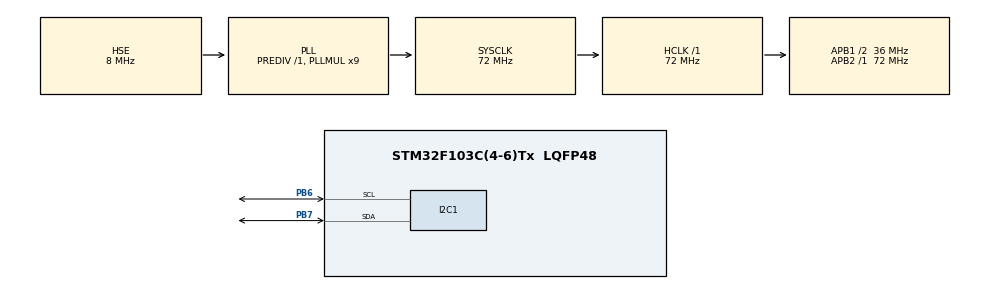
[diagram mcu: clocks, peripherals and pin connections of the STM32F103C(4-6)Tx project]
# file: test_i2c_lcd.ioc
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Mcu.Family=STM32F1
Mcu.Name=STM32F103C(4-6)Tx
Mcu.Package=LQFP48
NVIC.PriorityGroup=NVIC_PRIORITYGROUP_4
PA13.Mode=Serial_Wire
PA13.Signal=SYS_JTMS-SWDIO
PA14.Mode=Serial_Wire
PA14.Signal=SYS_JTCK-SWCLK
PB6.Mode=I2C
PB6.Signal=I2C1_SCL
PB7.Mode=I2C
PB7.Signal=I2C1_SDA
PD0-OSC_IN.Mode=HSE-External-Oscillator
PD0-OSC_IN.Signal=RCC_OSC_IN
PD1-OSC_OUT.Mode=HSE-External-Oscillator
PD1-OSC_OUT.Signal=RCC_OSC_OUT
ProjectManager.HeapSize=0x200
ProjectManager.StackSize=0x400
ProjectManager.TargetToolchain=MDK-ARM V5
RCC.AHBFreq_Value=72000000
RCC.APB1CLKDivider=RCC_HCLK_DIV2
RCC.APB1Freq_Value=36000000
RCC.APB1TimFreq_Value=72000000
RCC.APB2Freq_Value=72000000
RCC.APB2TimFreq_Value=72000000
RCC.HCLKFreq_Value=72000000
RCC.PLLMUL=RCC_PLL_MUL9
RCC.PLLSourceVirtual=RCC_PLLSOURCE_HSE
RCC.SYSCLKFreq_VALUE=72000000
RCC.SYSCLKSource=RCC_SYSCLKSOURCE_PLLCLK
RCC.USBFreq_Value=72000000
VP_TIM2_VS_ClockSourceINT.Mode=Internal
board=custom

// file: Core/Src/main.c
/* USER CODE BEGIN Header */
/**
  ******************************************************************************
  * @file           : main.c
  * @brief          : Main program body
  ******************************************************************************
  * @attention
  *
  * Copyright (c) 2024 STMicroelectronics.
  * All rights reserved.
  *
  * This software is licensed under terms that can be found in the LICENSE file
  * in the root directory of this software component.
  * If no LICENSE file comes with this software, it is provided AS-IS.
  *
  ******************************************************************************
  */
/* USER CODE END Header */
#include "main.h"
#include "i2c-lcd.h"
#include "string.h"

I2C_HandleTypeDef hi2c1;

TIM_HandleTypeDef htim2;

void SystemClock_Config(void);
static void MX_GPIO_Init(void);
static void MX_I2C1_Init(void);
static void MX_TIM2_Init(void);
/* USER CODE BEGIN PFP */
//#define LCD_Address 0x4E

//char dataLCD[100];

//void Lcd_write_command(char command){
//	char data_u, data_l;
//	uint8_t data_t[4];
//	data_u = (command & 0xf0);
//	data_l = ((command<<4) & 0xf0);
//	data_t[0] = data_u | 0x0C; //en=1, rs=0
//	data_t[1] = data_u | 0x08; //en=0, rs=0
//	data_t[2] = data_l | 0x0C; //en=1, rs=0
//	data_t[3] = data_l | 0x08; //en=0, rs=0
//	HAL_I2C_Master_Transmit(&hi2c1, LCD_Address,
//										(uint8_t *) data_t, 4, 100);
//}
//void Lcd_write_data(char data){
//	char data_u, data_l;
//	uint8_t data_t[4];
//	data_u = (data & 0xf0);
//	data_l = ((data<<4) & 0xf0);
//	data_t[0] = data_u | 0x0D; //en=1, rs=1
//	data_t[1] = data_u | 0x09; //en=0, rs=1
//	data_t[2] = data_l | 0x0D; //en=1, rs=1
//	data_t[3] = data_l | 0x09; //en=0, rs=1
//	HAL_I2C_Master_Transmit(&hi2c1, LCD_Address,
//										(uint8_t *) data_t, 4, 100);
//}
//void Lcd_init(void){
//	Lcd_write_command(0x03);
//	HAL_Delay(50);
//	Lcd_write_command(0x02);
//	HAL_Delay(50);
//	Lcd_write_command(0x06);
//	HAL_Delay(50);
//	Lcd_write_command(0x0c);
//	HAL_Delay(50);
//	Lcd_write_command(0x28);
//	HAL_Delay(50);
//	Lcd_write_command(0x80);
//}
//void Lcd_write_string (char *str){
//	while (*str) Lcd_write_data (*str++);
//}

//void Lcd_delete(void){
//	Lcd_write_command(0x01);//delete display
//}
/* USER CODE END PFP */

int main(void)
{

  /* MCU Configuration--------------------------------------------------------*/

  /* Reset of all peripherals, Initializes the Flash interface and the Systick. */
  HAL_Init();
  SystemClock_Config();
  MX_GPIO_Init();
  MX_I2C1_Init();
  MX_TIM2_Init();
	lcd_init();

//	Lcd_init();
//	Lcd_delete();
//	HAL_Delay(50);
//
//	Lcd_write_command(0x80);
//	Lcd_write_string("Hieu");
//	Lcd_write_command(0xC0);//row2
//	Lcd_write_string("Beo");
//	HAL_Delay(2000);
//	Lcd_delete();
//	HAL_Delay(50);

  /* Infinite loop */
  while (1)
  {
		lcd_put_cur(0,0);
		lcd_send_string("Hello Hieu");
		lcd_put_cur(1,1);
		lcd_send_string("OKE");
		HAL_Delay(1000);
		lcd_clear();
  }
}

void SystemClock_Config(void)
{
  RCC_OscInitTypeDef RCC_OscInitStruct = {0};
  RCC_ClkInitTypeDef RCC_ClkInitStruct = {0};

  /** Initializes the RCC Oscillators according to the specified parameters
  * in the RCC_OscInitTypeDef structure.
  */
  RCC_OscInitStruct.OscillatorType = RCC_OSCILLATORTYPE_HSE;
  RCC_OscInitStruct.HSEState = RCC_HSE_ON;
  RCC_OscInitStruct.HSEPredivValue = RCC_HSE_PREDIV_DIV1;
  RCC_OscInitStruct.HSIState = RCC_HSI_ON;
  RCC_OscInitStruct.PLL.PLLState = RCC_PLL_ON;
  RCC_OscInitStruct.PLL.PLLSource = RCC_PLLSOURCE_HSE;
  RCC_OscInitStruct.PLL.PLLMUL = RCC_PLL_MUL9;
  if (HAL_RCC_OscConfig(&RCC_OscInitStruct) != HAL_OK)
  {
    Error_Handler();
  }

  /** Initializes the CPU, AHB and APB buses clocks
  */
  RCC_ClkInitStruct.ClockType = RCC_CLOCKTYPE_HCLK|RCC_CLOCKTYPE_SYSCLK
                              |RCC_CLOCKTYPE_PCLK1|RCC_CLOCKTYPE_PCLK2;
  RCC_ClkInitStruct.SYSCLKSource = RCC_SYSCLKSOURCE_PLLCLK;
  RCC_ClkInitStruct.AHBCLKDivider = RCC_SYSCLK_DIV1;
  RCC_ClkInitStruct.APB1CLKDivider = RCC_HCLK_DIV2;
  RCC_ClkInitStruct.APB2CLKDivider = RCC_HCLK_DIV1;

  if (HAL_RCC_ClockConfig(&RCC_ClkInitStruct, FLASH_LATENCY_2) != HAL_OK)
  {
    Error_Handler();
  }
}

static void MX_I2C1_Init(void)
{

  hi2c1.Instance = I2C1;
  hi2c1.Init.ClockSpeed = 100000;
  hi2c1.Init.DutyCycle = I2C_DUTYCYCLE_2;
  hi2c1.Init.OwnAddress1 = 0;
  hi2c1.Init.AddressingMode = I2C_ADDRESSINGMODE_7BIT;
  hi2c1.Init.DualAddressMode = I2C_DUALADDRESS_DISABLE;
  hi2c1.Init.OwnAddress2 = 0;
  hi2c1.Init.GeneralCallMode = I2C_GENERALCALL_DISABLE;
  hi2c1.Init.NoStretchMode = I2C_NOSTRETCH_DISABLE;
  if (HAL_I2C_Init(&hi2c1) != HAL_OK)
  {
    Error_Handler();
  }

}

static void MX_TIM2_Init(void)
{

  TIM_ClockConfigTypeDef sClockSourceConfig = {0};
  TIM_MasterConfigTypeDef sMasterConfig = {0};

  htim2.Instance = TIM2;
  htim2.Init.Prescaler = 0;
  htim2.Init.CounterMode = TIM_COUNTERMODE_UP;
  htim2.Init.Period = 65535;
  htim2.Init.ClockDivision = TIM_CLOCKDIVISION_DIV1;
  htim2.Init.AutoReloadPreload = TIM_AUTORELOAD_PRELOAD_DISABLE;
  if (HAL_TIM_Base_Init(&htim2) != HAL_OK)
  {
    Error_Handler();
  }
  sClockSourceConfig.ClockSource = TIM_CLOCKSOURCE_INTERNAL;
  if (HAL_TIM_ConfigClockSource(&htim2, &sClockSourceConfig) != HAL_OK)
  {
    Error_Handler();
  }
  sMasterConfig.MasterOutputTrigger = TIM_TRGO_RESET;
  sMasterConfig.MasterSlaveMode = TIM_MASTERSLAVEMODE_DISABLE;
  if (HAL_TIMEx_MasterConfigSynchronization(&htim2, &sMasterConfig) != HAL_OK)
  {
    Error_Handler();
  }

}

static void MX_GPIO_Init(void)
{

  /* GPIO Ports Clock Enable */
  __HAL_RCC_GPIOD_CLK_ENABLE();
  __HAL_RCC_GPIOA_CLK_ENABLE();
  __HAL_RCC_GPIOB_CLK_ENABLE();

}

void Error_Handler(void)
{
  __disable_irq();
  while (1)
  {
  }
}
